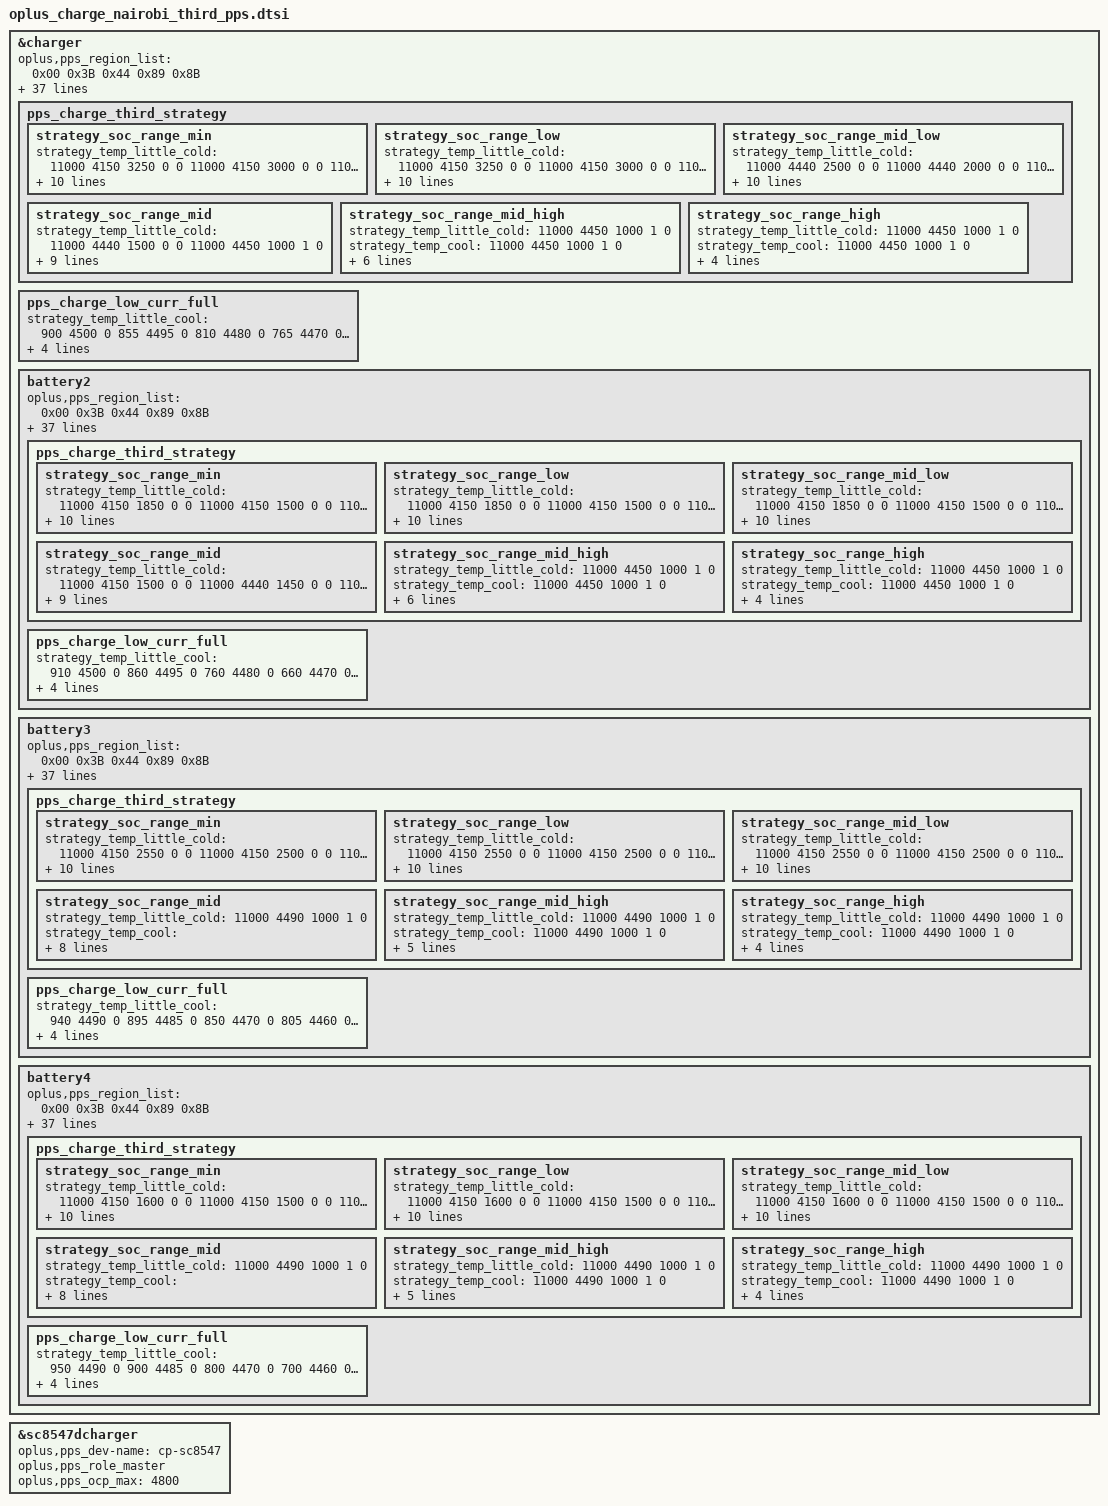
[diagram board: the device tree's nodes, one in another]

&charger {
	// 3rd PPS
	oplus,pps_region_list = <0x00 0x3B 0x44 0x89 0x8B>;
	oplus,pps_priority_list = <0x44>;
	oplus,svooc_current_limit_list = <0x44>;
	oplus,pps_ops = "cp-sc8547";
	oplus,pps_support_type = <4>;
	oplus,pps_support_third = <1>;
	oplus,pps_use_cp_vbat;
	oplus,pps_warm_allow_vol = <4000>;
	oplus,pps_warm_allow_soc = <50>;
	oplus,pps_strategy_normal_current = <4100>;//4.1A
	oplus,pps_strategy_common_chg_current = <4100>;//4.1A
	oplus,pps_over_high_or_low_current = <4100>;
	oplus,pps_timeout_third = <10800>;
	oplus,pps_timeout_oplus = <7200>;
	oplus,pps_ibat_over_third = <8200>;
	oplus,pps_ibat_over_oplus = <17000>;
	oplus,pps_full_ffc_vbat = <4500>;
	oplus,pps_full_cool_sw_vbat = <4460>;
	oplus,pps_full_normal_sw_vbat = <4460>;
	oplus,pps_full_normal_hw_vbat = <4470>;
	oplus,pps_full_warm_vbat = <4130>;
	oplus,pps_full_cool_sw_vbat_third = <4460>;
	oplus,pps_full_normal_sw_vbat_third = <4460>;
	oplus,pps_full_normal_hw_vbat_third = <4470>;
	oplus,pps_r_default = <120 10 10 15 15 15 15>;
	oplus,pps_rmos_mohm = <4>;
	oplus,pps_exit_ms = <500>;
	oplus,pps_r_limit = <280 200 140 90 50>;
	oplus,pps_strategy_batt_high_temp = <385 395 420 375 385 410>;
	oplus,pps_strategy_high_current = <3000 3000 2000 3000 3000 3000>;
	oplus,pps_charge_strategy_soc = <0 20 35 55 75 85 90>;
	oplus,pps_charge_strategy_temp = <50 120 160 210 350 440 510>;
	oplus,pps_low_curr_full_strategy_temp = <120 160 380 430>;

	pps_charge_third_strategy {
		// 0 ~ 20
		strategy_soc_range_min {
			strategy_temp_little_cold =	<11000 4150 3250 0 0
							11000 4150 3000 0 0
							11000 4440 2550 0 0
							11000 4440 2500 0 0
							11000 4440 2000 0 0
							11000 4440 1550 0 0
							11000 4440 1500 0 0
							11000 4450 1000 1 0>;
			strategy_temp_cool =		<11000 4150 3250 0 0
							11000 4150 3000 0 0
							11000 4440 2550 0 0
							11000 4440 2500 0 0
							11000 4440 2000 0 0
							11000 4440 1550 0 0
							11000 4440 1500 0 0
							11000 4450 1000 1 0>;
			strategy_temp_little_cool =	<11000 4150 4100 0 30
							11000 4150 4000 0 0
							11000 4150 3500 0 0
							11000 4230 3250 0 0
							11000 4230 3000 0 0
							11000 4440 2550 0 0
							11000 4440 2500 0 0
							11000 4440 2000 0 0
							11000 4440 1550 0 0
							11000 4440 1500 0 0
							11000 4450 1000 1 0>;
			strategy_temp_normal_low = 	<11000 4150 4100 0 30
							11000 4150 4000 0 0
							11000 4150 3500 0 0
							11000 4230 3250 0 0
							11000 4230 3000 0 0
							11000 4440 2550 0 0
							11000 4440 2500 0 0
							11000 4440 2000 0 0
							11000 4440 1550 0 0
							11000 4440 1500 0 0
							11000 4450 1000 1 0>;
			strategy_temp_normal_high =	<11000 4150 4100 0 30
							11000 4150 4000 0 0
							11000 4150 3500 0 0
							11000 4230 3250 0 0
							11000 4230 3000 0 0
							11000 4440 2550 0 0
							11000 4440 2500 0 0
							11000 4440 2000 0 0
							11000 4440 1550 0 0
							11000 4440 1500 0 0
							11000 4450 1000 1 0>;
			strategy_temp_warm =		<11000 4120 1850 0 0
							11000 4120 1500 0 0
							11000 4130 1000 1 0>;
		};
		// 20 ~ 35
		strategy_soc_range_low {
			strategy_temp_little_cold =	<11000 4150 3250 0 0
							11000 4150 3000 0 0
							11000 4440 2550 0 0
							11000 4440 2500 0 0
							11000 4440 2000 0 0
							11000 4440 1550 0 0
							11000 4440 1500 0 0
							11000 4450 1000 1 0>;
			strategy_temp_cool =		<11000 4150 3250 0 0
							11000 4150 3000 0 0
							11000 4440 2550 0 0
							11000 4440 2500 0 0
							11000 4440 2000 0 0
							11000 4440 1550 0 0
							11000 4440 1500 0 0
							11000 4450 1000 1 0>;
			strategy_temp_little_cool =	<11000 4150 4100 0 30
							11000 4150 4000 0 0
							11000 4150 3500 0 0
							11000 4230 3250 0 0
							11000 4230 3000 0 0
							11000 4440 2550 0 0
							11000 4440 2500 0 0
							11000 4440 2000 0 0
							11000 4440 1550 0 0
							11000 4440 1500 0 0
							11000 4450 1000 1 0>;
			strategy_temp_normal_low =	<11000 4150 4100 0 30
							11000 4150 4000 0 0
							11000 4150 3500 0 0
							11000 4230 3250 0 0
							11000 4230 3000 0 0
							11000 4440 2550 0 0
							11000 4440 2500 0 0
							11000 4440 2000 0 0
							11000 4440 1550 0 0
							11000 4440 1500 0 0
							11000 4450 1000 1 0>;
			strategy_temp_normal_high =	<11000 4150 4100 0 30
							11000 4150 4000 0 0
							11000 4150 3500 0 0
							11000 4230 3250 0 0
							11000 4230 3000 0 0
							11000 4440 2550 0 0
							11000 4440 2500 0 0
							11000 4440 2000 0 0
							11000 4440 1550 0 0
							11000 4440 1500 0 0
							11000 4450 1000 1 0>;
			strategy_temp_warm =		<11000 4120 1850 0 0
							11000 4120 1500 0 0
							11000 4130 1000 1 0>;
		};
		// 35 ~ 55
		strategy_soc_range_mid_low {
			strategy_temp_little_cold =	<11000 4440 2500 0 0
							11000 4440 2000 0 0
							11000 4440 1550 0 0
							11000 4440 1500 0 0
							11000 4450 1000 1 0>;
			strategy_temp_cool =		<11000 4150 3000 0 0
							11000 4440 2550 0 0
							11000 4440 2500 0 0
							11000 4440 2000 0 0
							11000 4440 1550 0 0
							11000 4440 1500 0 0
							11000 4450 1000 1 0>;
			strategy_temp_little_cool =	<11000 4230 3000 0 0
							11000 4440 2550 0 0
							11000 4440 2500 0 0
							11000 4440 2000 0 0
							11000 4440 1550 0 0
							11000 4440 1500 0 0
							11000 4450 1000 1 0>;
			strategy_temp_normal_low =	<11000 4150 4100 0 30
							11000 4150 4000 0 0
							11000 4150 3500 0 0
							11000 4230 3250 0 0
							11000 4230 3000 0 0
							11000 4440 2550 0 0
							11000 4440 2500 0 0
							11000 4440 2000 0 0
							11000 4440 1550 0 0
							11000 4440 1500 0 0
							11000 4450 1000 1 0>;
			strategy_temp_normal_high =	<11000 4150 4100 0 30
							11000 4150 4000 0 0
							11000 4150 3500 0 0
							11000 4230 3250 0 0
							11000 4230 3000 0 0
							11000 4440 2550 0 0
							11000 4440 2500 0 0
							11000 4440 2000 0 0
							11000 4440 1550 0 0
							11000 4440 1500 0 0
							11000 4450 1000 1 0>;
			strategy_temp_warm =		<11000 4120 1850 0 0
							11000 4120 1500 0 0
							11000 4130 1000 1 0>;
		};
		// 56 ~ 75
		strategy_soc_range_mid {
			strategy_temp_little_cold =	<11000 4440 1500 0 0
							11000 4450 1000 1 0>;
			strategy_temp_cool =		<11000 4440 2000 0 0
							11000 4440 1550 0 0
							11000 4440 1500 0 0
							11000 4450 1000 1 0>;
			strategy_temp_little_cool =	<11000 4440 2000 0 0
							11000 4440 1550 0 0
							11000 4440 1500 0 0
							11000 4450 1000 1 0>;
			strategy_temp_normal_low =	<11000 4440 2000 0 0
							11000 4440 1550 0 0
							11000 4440 1500 0 0
							11000 4450 1000 1 0>;
			strategy_temp_normal_high =	<11000 4440 2000 0 0
							11000 4440 1550 0 0
							11000 4440 1500 0 0
							11000 4450 1000 1 0>;
			strategy_temp_warm =		<11000 4130 1000 1 0>;
		};
		// 76 ~ 85
		strategy_soc_range_mid_high {
			strategy_temp_little_cold =	<11000 4450 1000 1 0>;
			strategy_temp_cool =		<11000 4450 1000 1 0>;
			strategy_temp_little_cool =	<11000 4450 1000 1 0>;
			strategy_temp_normal_low =	<11000 4440 1500 0 0
							11000 4450 1000 1 0>;
			strategy_temp_normal_high =	<11000 4440 1500 0 0
							11000 4450 1000 1 0>;
			strategy_temp_warm =		<11000 4130 1000 1 0>;
		};
		// 86 ~ 90
		strategy_soc_range_high {
			strategy_temp_little_cold =	<11000 4450 1000 1 0>;
			strategy_temp_cool =		<11000 4450 1000 1 0>;
			strategy_temp_little_cool =	<11000 4450 1000 1 0>;
			strategy_temp_normal_low =	<11000 4450 1000 1 0>;
			strategy_temp_normal_high =	<11000 4450 1000 1 0>;
			strategy_temp_warm =		<11000 4130 1000 1 0>;
		};
	};
	pps_charge_low_curr_full {
		strategy_temp_little_cool = 	<900 4500 0
						855 4495 0
						810 4480 0
						765 4470 0
						720 4460 1>;
		strategy_temp_normal_low =	<1100 4500 0
						1050 4495 0
						950 4480 0
						850 4470 0
						700 4460 1>;
		strategy_temp_normal_high = 	<1150 4500 0
						1100 4495 0
						1000 4480 0
						900 4470 0
						750 4460 1>;
	};
};

&charger {
	battery2 {
		// 3rd PPS
		oplus,pps_region_list = <0x00 0x3B 0x44 0x89 0x8B>;
		oplus,pps_priority_list = <0x44>;
		oplus,svooc_current_limit_list = <0x44>;
		oplus,pps_ops = "cp-sc8547";
		oplus,pps_support_type = <4>;
		oplus,pps_support_third = <1>;
		oplus,pps_use_cp_vbat;
		oplus,pps_warm_allow_vol = <4000>;
		oplus,pps_warm_allow_soc = <50>;
		oplus,pps_strategy_normal_current = <4100>;//4.1A
		oplus,pps_strategy_common_chg_current = <4100>;//4.1A
		oplus,pps_over_high_or_low_current = <4100>;
		oplus,pps_timeout_third = <10800>;
		oplus,pps_timeout_oplus = <7200>;
		oplus,pps_ibat_over_third = <8200>;
		oplus,pps_ibat_over_oplus = <17000>;
		oplus,pps_full_ffc_vbat = <4500>;
		oplus,pps_full_cool_sw_vbat = <4460>;
		oplus,pps_full_normal_sw_vbat = <4460>;
		oplus,pps_full_normal_hw_vbat = <4470>;
		oplus,pps_full_warm_vbat = <4130>;
		oplus,pps_full_cool_sw_vbat_third = <4460>;
		oplus,pps_full_normal_sw_vbat_third = <4460>;
		oplus,pps_full_normal_hw_vbat_third = <4470>;
		oplus,pps_r_default = <120 10 10 15 15 15 15>;
		oplus,pps_rmos_mohm = <4>;
		oplus,pps_exit_ms = <500>;
		oplus,pps_r_limit = <280 200 140 90 50>;
		oplus,pps_strategy_batt_high_temp = <385 395 420 375 385 410>;
		oplus,pps_strategy_high_current = <3000 3000 2000 3000 3000 3000>;
		oplus,pps_charge_strategy_soc = <0 20 35 55 75 85 90>;
		oplus,pps_charge_strategy_temp = <50 120 160 210 350 440 500>;
		oplus,pps_low_curr_full_strategy_temp = <120 160 380 430>;

		pps_charge_third_strategy {
			// 0 ~ 20
			strategy_soc_range_min {
				strategy_temp_little_cold =	<11000 4150 1850 0 0
								11000 4150 1500 0 0
								11000 4440 1450 0 0
								11000 4450 1000 1 0>;
				strategy_temp_cool =		<11000 4150 1850 0 0
								11000 4150 1500 0 0
								11000 4440 1450 0 0
								11000 4450 1000 1 0>;
				strategy_temp_little_cool =	<11000 4200 4100 0 30
								11000 4200 4000 0 0
								11000 4200 3500 0 0
								11000 4200 3000 0 0
								11000 4230 2800 0 0
								11000 4230 2500 0 0
								11000 4440 2200 0 0
								11000 4440 2000 0 0
								11000 4440 1500 0 0
								11000 4440 1450 0 0
								11000 4450 1000 1 0>;
				strategy_temp_normal_low = <11000 4200 4100 0 30
								11000 4200 4000 0 0
								11000 4200 3500 0 0
								11000 4200 3000 0 0
								11000 4230 2800 0 0
								11000 4230 2500 0 0
								11000 4440 2200 0 0
								11000 4440 2000 0 0
								11000 4440 1500 0 0
								11000 4440 1450 0 0
								11000 4450 1000 1 0>;
				strategy_temp_normal_high =	<11000 4200 4100 0 30
								11000 4200 4000 0 0
								11000 4200 3500 0 0
								11000 4200 3000 0 0
								11000 4230 2800 0 0
								11000 4230 2500 0 0
								11000 4440 2200 0 0
								11000 4440 2000 0 0
								11000 4440 1500 0 0
								11000 4440 1450 0 0
								11000 4450 1000 1 0>;
				strategy_temp_warm =		<11000 4120 2000 0 0
								11000 4120 1500 0 0
								11000 4130 1000 1 0>;
			};
			// 20 ~ 35
			strategy_soc_range_low {
				strategy_temp_little_cold =	<11000 4150 1850 0 0
								11000 4150 1500 0 0
								11000 4440 1450 0 0
								11000 4450 1000 1 0>;
				strategy_temp_cool =		<11000 4150 1850 0 0
								11000 4150 1500 0 0
								11000 4440 1450 0 0
								11000 4450 1000 1 0>;
				strategy_temp_little_cool =	<11000 4200 4100 0 30
								11000 4200 4000 0 0
								11000 4200 3500 0 0
								11000 4200 3000 0 0
								11000 4230 2800 0 0
								11000 4230 2500 0 0
								11000 4440 2200 0 0
								11000 4440 2000 0 0
								11000 4440 1500 0 0
								11000 4440 1450 0 0
								11000 4450 1000 1 0>;
				strategy_temp_normal_low =	<11000 4200 4100 0 30
								11000 4200 4000 0 0
								11000 4200 3500 0 0
								11000 4200 3000 0 0
								11000 4230 2800 0 0
								11000 4230 2500 0 0
								11000 4440 2200 0 0
								11000 4440 2000 0 0
								11000 4440 1500 0 0
								11000 4440 1450 0 0
								11000 4450 1000 1 0>;
				strategy_temp_normal_high =	<11000 4200 4100 0 30
								11000 4200 4000 0 0
								11000 4200 3500 0 0
								11000 4200 3000 0 0
								11000 4230 2800 0 0
								11000 4230 2500 0 0
								11000 4440 2200 0 0
								11000 4440 2000 0 0
								11000 4440 1500 0 0
								11000 4440 1450 0 0
								11000 4450 1000 1 0>;
				strategy_temp_warm =		<11000 4120 2000 0 0
								11000 4120 1500 0 0
								11000 4130 1000 1 0>;
			};
			// 35 ~ 55
			strategy_soc_range_mid_low {
				strategy_temp_little_cold =	<11000 4150 1850 0 0
								11000 4150 1500 0 0
								11000 4440 1450 0 0
								11000 4450 1000 1 0>;
				strategy_temp_cool =		<11000 4150 1850 0 0
								11000 4150 1500 0 0
								11000 4440 1450 0 0
								11000 4450 1000 1 0>;
				strategy_temp_little_cool =	<11000 4200 3000 0 0
								11000 4230 2800 0 0
								11000 4230 2500 0 0
								11000 4440 2200 0 0
								11000 4440 2000 0 0
								11000 4440 1500 0 0
								11000 4440 1450 0 0
								11000 4450 1000 1 0>;
				strategy_temp_normal_low =	<11000 4200 4100 0 30
								11000 4200 4000 0 0
								11000 4200 3500 0 0
								11000 4200 3000 0 0
								11000 4230 2800 0 0
								11000 4230 2500 0 0
								11000 4440 2200 0 0
								11000 4440 2000 0 0
								11000 4440 1500 0 0
								11000 4440 1450 0 0
								11000 4450 1000 1 0>;
				strategy_temp_normal_high =	<11000 4200 4100 0 30
								11000 4200 4000 0 0
								11000 4200 3500 0 0
								11000 4200 3000 0 0
								11000 4230 2800 0 0
								11000 4230 2500 0 0
								11000 4440 2200 0 0
								11000 4440 2000 0 0
								11000 4440 1500 0 0
								11000 4440 1450 0 0
								11000 4450 1000 1 0>;
				strategy_temp_warm =		<11000 4120 2000 0 0
								11000 4120 1500 0 0
								11000 4130 1000 1 0>;
			};
			// 56 ~ 75
			strategy_soc_range_mid {
				strategy_temp_little_cold =	<11000 4150 1500 0 0
								11000 4440 1450 0 0
								11000 4450 1000 1 0>;
				strategy_temp_cool =		<11000 4150 1850 0 0
								11000 4150 1500 0 0
								11000 4440 1450 0 0
								11000 4450 1000 1 0>;
				strategy_temp_little_cool =	<11000 4440 2000 0 0
								11000 4440 1500 0 0
								11000 4440 1450 0 0
								11000 4450 1000 1 0>;
				strategy_temp_normal_low =	<11000 4440 2000 0 0
								11000 4440 1500 0 0
								11000 4440 1450 0 0
								11000 4450 1000 1 0>;
				strategy_temp_normal_high =	<11000 4440 2000 0 0
								11000 4440 1500 0 0
								11000 4440 1450 0 0
								11000 4450 1000 1 0>;
				strategy_temp_warm =		<11000 4130 1000 1 0>;
			};
			// 76 ~ 85
			strategy_soc_range_mid_high {
				strategy_temp_little_cold =	<11000 4450 1000 1 0>;
				strategy_temp_cool =		<11000 4450 1000 1 0>;
				strategy_temp_little_cool =	<11000 4450 1000 1 0>;
				strategy_temp_normal_low =	<11000 4440 1500 0 0
								11000 4440 1450 0 0
								11000 4450 1000 1 0>;
				strategy_temp_normal_high =	<11000 4440 1500 0 0
								11000 4440 1450 0 0
								11000 4450 1000 1 0>;
				strategy_temp_warm =		<11000 4130 1000 1 0>;
			};
			// 86 ~ 90
			strategy_soc_range_high {
				strategy_temp_little_cold =	<11000 4450 1000 1 0>;
				strategy_temp_cool =		<11000 4450 1000 1 0>;
				strategy_temp_little_cool =	<11000 4450 1000 1 0>;
				strategy_temp_normal_low =	<11000 4450 1000 1 0>;
				strategy_temp_normal_high =	<11000 4450 1000 1 0>;
				strategy_temp_warm =		<11000 4130 1000 1 0>;
			};
		};
		pps_charge_low_curr_full {
			strategy_temp_little_cool = 	<910 4500 0
							860 4495 0
							760 4480 0
							660 4470 0
							510 4460 1>;
			strategy_temp_normal_low =	<1750 4500 0
							1700 4495 0
							1600 4480 0
							1500 4470 0
							1350 4460 1>;
			strategy_temp_normal_high = 	<1950 4500 0
							1900 4495 0
							1800 4480 0
							1700 4470 0
							1550 4460 1>;
		};
	};
};

&charger {
	battery3 {
		// 3rd PPS
		oplus,pps_region_list = <0x00 0x3B 0x44 0x89 0x8B>;
		oplus,pps_priority_list = <0x44>;
		oplus,svooc_current_limit_list = <0x44>;
		oplus,pps_ops = "cp-sc8547";
		oplus,pps_support_type = <4>;
		oplus,pps_support_third = <1>;
		oplus,pps_use_cp_vbat;
		oplus,pps_warm_allow_vol = <4000>;
		oplus,pps_warm_allow_soc = <50>;
		oplus,pps_strategy_normal_current = <4100>;//4.1A
		oplus,pps_strategy_common_chg_current = <4100>;//4.1A
		oplus,pps_over_high_or_low_current = <4100>;
		oplus,pps_timeout_third = <10800>;
		oplus,pps_timeout_oplus = <7200>;
		oplus,pps_ibat_over_third = <11000>;
		oplus,pps_ibat_over_oplus = <17000>;
		oplus,pps_full_ffc_vbat = <4500>;
		oplus,pps_full_cool_sw_vbat = <4490>;
		oplus,pps_full_normal_sw_vbat = <4490>;
		oplus,pps_full_normal_hw_vbat = <4500>;
		oplus,pps_full_warm_vbat = <4130>;
		oplus,pps_full_cool_sw_vbat_third = <4490>;
		oplus,pps_full_normal_sw_vbat_third = <4490>;
		oplus,pps_full_normal_hw_vbat_third = <4500>;
		oplus,pps_r_default = <120 10 10 15 15 15 15>;
		oplus,pps_rmos_mohm = <4>;
		oplus,pps_exit_ms = <500>;
		oplus,pps_r_limit = <280 200 140 90 50>;
		oplus,pps_strategy_batt_high_temp = <385 395 420 375 385 410>;
		oplus,pps_strategy_high_current = <3000 3000 2000 3000 3000 3000>;
		oplus,pps_charge_strategy_soc = <0 20 35 50 75 85 90>;
		oplus,pps_charge_strategy_temp = <0 50 120 160 350 440 510>;
		oplus,pps_low_curr_full_strategy_temp = <120 160 380 440>;

		pps_charge_third_strategy {
			// 0 ~ 20
			strategy_soc_range_min {
				strategy_temp_little_cold =	<11000 4150 2550 0 0
								11000 4150 2500 0 0
								11000 4150 2000 0 0
								11000 4480 1750 0 0
								11000 4480 1500 0 0
								11000 4490 1000 1 0>;
				strategy_temp_cool =		<11000 4150 3700 0 0
								11000 4150 3500 0 0
								11000 4150 3000 0 0
								11000 4480 2550 0 0
								11000 4480 2500 0 0
								11000 4480 2000 0 0
								11000 4480 1500 0 0
								11000 4490 1000 1 0>;
				strategy_temp_little_cool =	<11000 4470 4100 0 0
								11000 4470 4000 0 0
								11000 4470 3500 0 0
								11000 4470 3000 0 0
								11000 4480 2900 0 0
								11000 4480 2500 0 0
								11000 4480 2000 0 0
								11000 4480 1500 0 0
								11000 4490 1000 1 0>;
				strategy_temp_normal_low = 	<11000 4470 4100 0 0
								11000 4470 4000 0 0
								11000 4470 3500 0 0
								11000 4470 3000 0 0
								11000 4480 2900 0 0
								11000 4480 2500 0 0
								11000 4480 2000 0 0
								11000 4480 1500 0 0
								11000 4490 1000 1 0>;
				strategy_temp_normal_high =	<11000 4450 4100 0 0
								11000 4450 4000 0 0
								11000 4450 3500 0 0
								11000 4450 3000 0 0
								11000 4460 2900 0 0
								11000 4460 2500 0 0
								11000 4460 2000 0 0
								11000 4460 1500 0 0
								11000 4470 1000 1 0>;
				strategy_temp_warm =		<11000 4120 2000 0 0
								11000 4120 1500 0 0
								11000 4130 1000 1 0>;
			};
			// 20 ~ 35
			strategy_soc_range_low {
				strategy_temp_little_cold =	<11000 4150 2550 0 0
								11000 4150 2500 0 0
								11000 4150 2000 0 0
								11000 4480 1750 0 0
								11000 4480 1500 0 0
								11000 4490 1000 1 0>;
				strategy_temp_cool =		<11000 4150 3700 0 0
								11000 4150 3500 0 0
								11000 4150 3000 0 0
								11000 4480 2550 0 0
								11000 4480 2500 0 0
								11000 4480 2000 0 0
								11000 4480 1500 0 0
								11000 4490 1000 1 0>;
				strategy_temp_little_cool =	<11000 4470 4100 0 0
								11000 4470 4000 0 0
								11000 4470 3500 0 0
								11000 4470 3000 0 0
								11000 4480 2900 0 0
								11000 4480 2500 0 0
								11000 4480 2000 0 0
								11000 4480 1500 0 0
								11000 4490 1000 1 0>;
				strategy_temp_normal_low = 	<11000 4470 4100 0 0
								11000 4470 4000 0 0
								11000 4470 3500 0 0
								11000 4470 3000 0 0
								11000 4480 2900 0 0
								11000 4480 2500 0 0
								11000 4480 2000 0 0
								11000 4480 1500 0 0
								11000 4490 1000 1 0>;
				strategy_temp_normal_high =	<11000 4450 4100 0 0
								11000 4450 4000 0 0
								11000 4450 3500 0 0
								11000 4450 3000 0 0
								11000 4460 2900 0 0
								11000 4460 2500 0 0
								11000 4460 2000 0 0
								11000 4460 1500 0 0
								11000 4470 1000 1 0>;
				strategy_temp_warm =		<11000 4120 2000 0 0
								11000 4120 1500 0 0
								11000 4130 1000 1 0>;
			};
			// 35 ~ 55
			strategy_soc_range_mid_low {
				strategy_temp_little_cold =	<11000 4150 2550 0 0
								11000 4150 2500 0 0
								11000 4150 2000 0 0
								11000 4480 1750 0 0
								11000 4480 1500 0 0
								11000 4490 1000 1 0>;
				strategy_temp_cool =		<11000 4150 3700 0 0
								11000 4150 3500 0 0
								11000 4150 3000 0 0
								11000 4480 2550 0 0
								11000 4480 2500 0 0
								11000 4480 2000 0 0
								11000 4480 1500 0 0
								11000 4490 1000 1 0>;
				strategy_temp_little_cool =	<11000 4470 4100 0 0
								11000 4470 4000 0 0
								11000 4470 3500 0 0
								11000 4470 3000 0 0
								11000 4480 2900 0 0
								11000 4480 2500 0 0
								11000 4480 2000 0 0
								11000 4480 1500 0 0
								11000 4490 1000 1 0>;
				strategy_temp_normal_low = 	<11000 4470 4100 0 0
								11000 4470 4000 0 0
								11000 4470 3500 0 0
								11000 4470 3000 0 0
								11000 4480 2900 0 0
								11000 4480 2500 0 0
								11000 4480 2000 0 0
								11000 4480 1500 0 0
								11000 4490 1000 1 0>;
				strategy_temp_normal_high =	<11000 4450 4100 0 0
								11000 4450 4000 0 0
								11000 4450 3500 0 0
								11000 4450 3000 0 0
								11000 4460 2900 0 0
								11000 4460 2500 0 0
								11000 4460 2000 0 0
								11000 4460 1500 0 0
								11000 4470 1000 1 0>;
				strategy_temp_warm =		<11000 4120 2000 0 0
								11000 4120 1500 0 0
								11000 4130 1000 1 0>;
			};
			// 56 ~ 75
			strategy_soc_range_mid {
				strategy_temp_little_cold =	<11000 4490 1000 1 0>;
				strategy_temp_cool =		<11000 4480 1500 0 0
								11000 4490 1000 1 0>;
				strategy_temp_little_cool =	<11000 4480 2000 0 0
								11000 4480 1500 0 0
								11000 4490 1000 1 0>;
				strategy_temp_normal_low =	<11000 4480 2000 0 0
								11000 4480 1500 0 0
								11000 4490 1000 1 0>;
				strategy_temp_normal_high =	<11000 4460 2000 0 0
								11000 4460 1500 0 0
								11000 4470 1000 1 0>;
				strategy_temp_warm =		<11000 4130 1000 1 0>;
			};
			// 76 ~ 85
			strategy_soc_range_mid_high {
				strategy_temp_little_cold =	<11000 4490 1000 1 0>;
				strategy_temp_cool =		<11000 4490 1000 1 0>;
				strategy_temp_little_cool =	<11000 4490 1000 1 0>;
				strategy_temp_normal_low =	<11000 4490 1000 1 0>;
				strategy_temp_normal_high =	<11000 4460 1500 0 0
								11000 4470 1000 1 0>;
				strategy_temp_warm =		<11000 4130 1000 1 0>;
			};
			// 86 ~ 90
			strategy_soc_range_high {
				strategy_temp_little_cold =	<11000 4490 1000 1 0>;
				strategy_temp_cool =		<11000 4490 1000 1 0>;
				strategy_temp_little_cool =	<11000 4490 1000 1 0>;
				strategy_temp_normal_low =	<11000 4490 1000 1 0>;
				strategy_temp_normal_high =	<11000 4490 1000 1 0>;
				strategy_temp_warm =		<11000 4130 1000 1 0>;
			};
		};
		pps_charge_low_curr_full {
			strategy_temp_little_cool = 	<940 4490 0
							895 4485 0
							850 4470 0
							805 4460 0
							760 4450 1>;
			strategy_temp_normal_low =	<1450 4490 0
							1400 4485 0
							1300 4470 0
							1200 4460 0
							1050 4450 1>;
			strategy_temp_normal_high = 	<2160 4470 0
							1960 4465 0
							1960 4450 0
							1960 4440 0
							1000 4430 1>;
		};
	};
};

&charger {
	battery4 {
		// 3rd PPS
		oplus,pps_region_list = <0x00 0x3B 0x44 0x89 0x8B>;
		oplus,pps_priority_list = <0x44>;
		oplus,svooc_current_limit_list = <0x44>;
		oplus,pps_ops = "cp-sc8547";
		oplus,pps_support_type = <4>;
		oplus,pps_support_third = <1>;
		oplus,pps_use_cp_vbat;
		oplus,pps_warm_allow_vol = <4000>;
		oplus,pps_warm_allow_soc = <50>;
		oplus,pps_strategy_normal_current = <4100>;//4.1A
		oplus,pps_strategy_common_chg_current = <4100>;//4.1A
		oplus,pps_over_high_or_low_current = <4100>;
		oplus,pps_timeout_third = <10800>;
		oplus,pps_timeout_oplus = <7200>;
		oplus,pps_ibat_over_third = <11000>;
		oplus,pps_ibat_over_oplus = <17000>;
		oplus,pps_full_ffc_vbat = <4500>;
		oplus,pps_full_cool_sw_vbat = <4490>;
		oplus,pps_full_normal_sw_vbat = <4490>;
		oplus,pps_full_normal_hw_vbat = <4500>;
		oplus,pps_full_warm_vbat = <4130>;
		oplus,pps_full_cool_sw_vbat_third = <4490>;
		oplus,pps_full_normal_sw_vbat_third = <4490>;
		oplus,pps_full_normal_hw_vbat_third = <4500>;
		oplus,pps_r_default = <120 10 10 15 15 15 15>;
		oplus,pps_rmos_mohm = <4>;
		oplus,pps_exit_ms = <500>;
		oplus,pps_r_limit = <280 200 140 90 50>;
		oplus,pps_strategy_batt_high_temp = <385 395 420 375 385 410>;
		oplus,pps_strategy_high_current = <3000 3000 2000 3000 3000 3000>;
		oplus,pps_charge_strategy_soc = <0 20 35 50 75 85 90>;
		oplus,pps_charge_strategy_temp = <0 50 120 160 350 440 510>;
		oplus,pps_low_curr_full_strategy_temp = <120 160 380 440>;

		pps_charge_third_strategy {
			// 0 ~ 20
			strategy_soc_range_min {
				strategy_temp_little_cold =	<11000 4150 1600 0 0
								11000 4150 1500 0 0
								11000 4480 1150 0 0
								11000 4490 1000 1 0>;
				strategy_temp_cool =		<11000 4150 2300 0 0
								11000 4150 2000 0 0
								11000 4480 1600 0 0
								11000 4480 1500 0 0
								11000 4490 1000 1 0>;
				strategy_temp_little_cool =	<11000 4150 3250 0 0
								11000 4150 3000 0 0
								11000 4470 2600 0 0
								11000 4470 2500 0 0
								11000 4470 2000 0 0
								11000 4480 1700 0 0
								11000 4480 1500 0 0
								11000 4490 1000 1 0>;
				strategy_temp_normal_low = 	<11000 4180 4100 0 0
								11000 4180 4000 0 0
								11000 4180 3500 0 0
								11000 4460 3250 0 0
								11000 4460 3000 0 0
								11000 4470 2600 0 0
								11000 4470 2500 0 0
								11000 4470 2000 0 0
								11000 4480 1700 0 0
								11000 4480 1500 0 0
								11000 4490 1000 1 0>;
				strategy_temp_normal_high =	<11000 4180 4100 0 0
								11000 4180 4000 0 0
								11000 4180 3500 0 0
								11000 4440 3250 0 0
								11000 4440 3000 0 0
								11000 4450 2600 0 0
								11000 4450 2500 0 0
								11000 4450 2000 0 0
								11000 4460 1700 0 0
								11000 4460 1500 0 0
								11000 4470 1000 1 0>;
				strategy_temp_warm =		<11000 4120 1300 0 0
								11000 4130 1000 1 0>;
			};
			// 20 ~ 35
			strategy_soc_range_low {
				strategy_temp_little_cold =	<11000 4150 1600 0 0
								11000 4150 1500 0 0
								11000 4480 1150 0 0
								11000 4490 1000 1 0>;
				strategy_temp_cool =		<11000 4150 2300 0 0
								11000 4150 2000 0 0
								11000 4480 1600 0 0
								11000 4480 1500 0 0
								11000 4490 1000 1 0>;
				strategy_temp_little_cool =	<11000 4150 3250 0 0
								11000 4150 3000 0 0
								11000 4470 2600 0 0
								11000 4470 2500 0 0
								11000 4470 2000 0 0
								11000 4480 1700 0 0
								11000 4480 1500 0 0
								11000 4490 1000 1 0>;
				strategy_temp_normal_low = 	<11000 4180 4100 0 0
								11000 4180 4000 0 0
								11000 4180 3500 0 0
								11000 4460 3250 0 0
								11000 4460 3000 0 0
								11000 4470 2600 0 0
								11000 4470 2500 0 0
								11000 4470 2000 0 0
								11000 4480 1700 0 0
								11000 4480 1500 0 0
								11000 4490 1000 1 0>;
				strategy_temp_normal_high =	<11000 4180 4100 0 0
								11000 4180 4000 0 0
								11000 4180 3500 0 0
								11000 4440 3250 0 0
								11000 4440 3000 0 0
								11000 4450 2600 0 0
								11000 4450 2500 0 0
								11000 4450 2000 0 0
								11000 4460 1700 0 0
								11000 4460 1500 0 0
								11000 4470 1000 1 0>;
				strategy_temp_warm =		<11000 4120 1300 0 0
								11000 4130 1000 1 0>;
			};
			// 35 ~ 55
			strategy_soc_range_mid_low {
				strategy_temp_little_cold =	<11000 4150 1600 0 0
								11000 4150 1500 0 0
								11000 4480 1150 0 0
								11000 4490 1000 1 0>;
				strategy_temp_cool =		<11000 4150 2300 0 0
								11000 4150 2000 0 0
								11000 4480 1600 0 0
								11000 4480 1500 0 0
								11000 4490 1000 1 0>;
				strategy_temp_little_cool =	<11000 4150 3250 0 0
								11000 4150 3000 0 0
								11000 4470 2600 0 0
								11000 4470 2500 0 0
								11000 4470 2000 0 0
								11000 4480 1700 0 0
								11000 4480 1500 0 0
								11000 4490 1000 1 0>;
				strategy_temp_normal_low = 	<11000 4180 4100 0 0
								11000 4180 4000 0 0
								11000 4180 3500 0 0
								11000 4460 3250 0 0
								11000 4460 3000 0 0
								11000 4470 2600 0 0
								11000 4470 2500 0 0
								11000 4470 2000 0 0
								11000 4480 1700 0 0
								11000 4480 1500 0 0
								11000 4490 1000 1 0>;
				strategy_temp_normal_high =	<11000 4180 4100 0 0
								11000 4180 4000 0 0
								11000 4180 3500 0 0
								11000 4440 3250 0 0
								11000 4440 3000 0 0
								11000 4450 2600 0 0
								11000 4450 2500 0 0
								11000 4450 2000 0 0
								11000 4460 1700 0 0
								11000 4460 1500 0 0
								11000 4470 1000 1 0>;
				strategy_temp_warm =		<11000 4120 1300 0 0
								11000 4130 1000 1 0>;
			};
			// 56 ~ 75
			strategy_soc_range_mid {
				strategy_temp_little_cold =	<11000 4490 1000 1 0>;
				strategy_temp_cool =		<11000 4480 1500 0 0
								11000 4490 1000 1 0>;
				strategy_temp_little_cool =	<11000 4470 2000 0 0
								11000 4480 1700 0 0
								11000 4480 1500 0 0
								11000 4490 1000 1 0>;
				strategy_temp_normal_low =	<11000 4470 2000 0 0
								11000 4480 1700 0 0
								11000 4480 1500 0 0
								11000 4490 1000 1 0>;
				strategy_temp_normal_high =	<11000 4450 2000 0 0
								11000 4460 1700 0 0
								11000 4460 1500 0 0
								11000 4470 1000 1 0>;
				strategy_temp_warm =		<11000 4130 1000 1 0>;
			};
			// 76 ~ 85
			strategy_soc_range_mid_high {
				strategy_temp_little_cold =	<11000 4490 1000 1 0>;
				strategy_temp_cool =		<11000 4490 1000 1 0>;
				strategy_temp_little_cool =	<11000 4490 1000 1 0>;
				strategy_temp_normal_low =	<11000 4490 1000 1 0>;
				strategy_temp_normal_high =	<11000 4460 1500 0 0
								11000 4470 1000 1 0>;
				strategy_temp_warm =		<11000 4130 1000 1 0>;
			};
			// 86 ~ 90
			strategy_soc_range_high {
				strategy_temp_little_cold =	<11000 4490 1000 1 0>;
				strategy_temp_cool =		<11000 4490 1000 1 0>;
				strategy_temp_little_cool =	<11000 4490 1000 1 0>;
				strategy_temp_normal_low =	<11000 4490 1000 1 0>;
				strategy_temp_normal_high =	<11000 4490 1000 1 0>;
				strategy_temp_warm =		<11000 4130 1000 1 0>;
			};
		};
		pps_charge_low_curr_full {
			strategy_temp_little_cool = 	<950 4490 0
							900 4485 0
							800 4470 0
							700 4460 0
							550 4450 1>;
			strategy_temp_normal_low =	<1950 4490 0
							1900 4485 0
							1800 4470 0
							1700 4460 0
							1550 4450 1>;
			strategy_temp_normal_high = 	<2960 4470 0
							2760 4465 0
							2210 4450 0
							1660 4440 0
							1000 4430 1>;
		};
	};
};

&sc8547dcharger {
	oplus,pps_dev-name = "cp-sc8547";
	oplus,pps_role_master;
	oplus,pps_ocp_max = <4800>;
};

